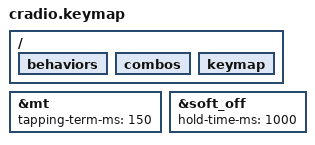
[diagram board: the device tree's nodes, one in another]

#include <behaviors.dtsi>
#include <dt-bindings/zmk/keys.h>
#include <dt-bindings/zmk/mouse.h>
#include <dt-bindings/zmk/bt.h>
#include <dt-bindings/zmk/reset.h>
#include <dt-bindings/zmk/outputs.h>
#include "kscan.dtsi"
#include "layers.dtsi"

&mt {
  tapping-term-ms = <150>;
};

&soft_off {
  hold-time-ms = <1000>;
};

/ {
  behaviors {
#include "behaviors.dtsi"
  };

  combos {
#include "combos.dtsi"
  };

  keymap {
#include "keymap.dtsi"
  };
};

